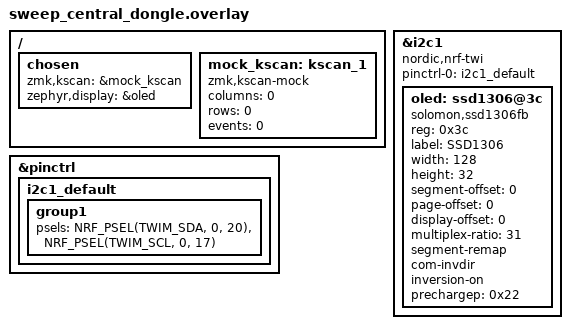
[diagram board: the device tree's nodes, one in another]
#include "sweep.dtsi"

/ {
    chosen {
        zmk,kscan = &mock_kscan;
        zephyr,display = &oled;
    };

    mock_kscan: kscan_1 {
        compatible = "zmk,kscan-mock";
        columns = <0>;
        rows = <0>;
        events = <0>;
    };
};

/delete-node/ &default_kscan;  // Only required if the dongle uses a different board than peripherals

&i2c1 {
    status = "okay";
    compatible = "nordic,nrf-twi";
    
    pinctrl-0 = <&i2c1_default>;
    pinctrl-names = "default";

    oled: ssd1306@3c {
        compatible = "solomon,ssd1306fb";
        reg = <0x3c>;
        label = "SSD1306";
        width = <128>;
        height = <32>;   // Adjust for 0.91-inch display
        segment-offset = <0>;
        page-offset = <0>;
        display-offset = <0>;
        multiplex-ratio = <31>;
        segment-remap;
        com-invdir;
        inversion-on;
        prechargep = <0x22>;
    };
};

/* Define pin control settings */
&pinctrl {
    i2c1_default: i2c1_default {
        group1 {
            psels = <NRF_PSEL(TWIM_SDA, 0, 20)>, <NRF_PSEL(TWIM_SCL, 0, 17)>;
        };
    };
};
